# max32665 register map
Vendor: Maxim-Integrated; Series: ARMCM3; File version: 1.1
CPU: CM4 r2p1, little endian, MPU, FPU, 3 interrupt priority bits
Registers are 32-bit, read-write, reset 0x0 unless marked. A register's access mark holds for its fields unless they carry their own. Offsets are from the block's base; [hi:lo] are bit positions; 'fields as' and 'values as' point back to an identical list.

## TRIMSIR — Trim System Initilazation Registers
Base 0x40005400
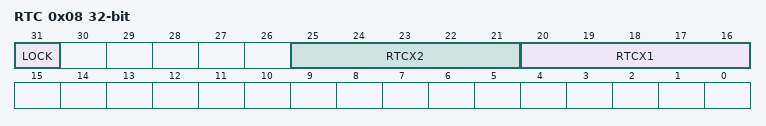
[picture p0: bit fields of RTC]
0x08 RTC — System Init. Configuration Register 2.
  [31] LOCK
  [25:21] RTCX2 — RTC X2 Trim.
  [20:16] RTCX1 — RTC X1 Trim.
0x34 SIR13 — System Init. Configuration Register 13.
  [1:0] SIMOCLKDIV — SIMO Clock Divide while in LP mode.
0x44 SIR17 — System Init. Configuration Register 17.
  [7:6] BUCKCLKSELLP — BUCK Clock Select Low Power Mode.

## WDT0 — Watchdog Timer 0
Base 0x40003000
Same registers: WDT1 0x40003400, WDT2 0x40003800
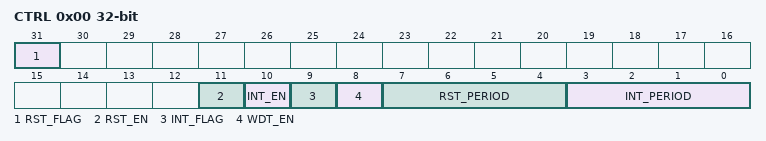
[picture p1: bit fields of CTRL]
0x00 CTRL (reset mask 0x7FFFF000) — Watchdog Timer Control Register.
  [31] RST_FLAG — Watchdog Timer Reset Flag.
    0=noEvent (The event has not occurred.); 1=occurred (The event has occurred.)
  [11] RST_EN — Watchdog Timer Reset Enable.
    0=dis (Disable.); 1=en (Enable.)
  [10] INT_EN — Watchdog Timer Interrupt Enable.
    0=dis (Disable.); 1=en (Enable.)
  [9] INT_FLAG write-1-clears — Watchdog Timer Interrupt Flag.
    0=inactive (No interrupt is pending.); 1=pending (An interrupt is pending.)
  [8] WDT_EN — Watchdog Timer Enable.
    0=dis (Disable.); 1=en (Enable.)
  [7:4] RST_PERIOD — Watchdog Reset Period. The watchdog timer will assert a reset, if enabled, if the CPU does not write the watchdog reset sequence to the WDT_RST register before the watchdog timer has counted this time period since the last timer reset.
    0=wdt2pow31 (2**31 clock cycles.); 1=wdt2pow30 (2**30 clock cycles.); 2=wdt2pow29 (2**29 clock cycles.); 3=wdt2pow28 (2**28 clock cycles.); 4=wdt2pow27 (2^27 clock cycles.); 5=wdt2pow26 (2**26 clock cycles.); 6=wdt2pow25 (2**25 clock cycles.); 7=wdt2pow24 (2**24 clock cycles.); 8=wdt2pow23 (2**23 clock cycles.); 9=wdt2pow22 (2**22 clock cycles.); 10=wdt2pow21 (2**21 clock cycles.); 11=wdt2pow20 (2**20 clock cycles.); 12=wdt2pow19 (2**19 clock cycles.); 13=wdt2pow18 (2**18 clock cycles.); 14=wdt2pow17 (2**17 clock cycles.); 15=wdt2pow16 (2**16 clock cycles.)
  [3:0] INT_PERIOD — Watchdog Interrupt Period. The watchdog timer will assert an interrupt, if enabled, if the CPU does not write the watchdog reset sequence to the WDT_RST register before the watchdog timer has counted this time period since the last timer reset.
    values as RST_PERIOD
0x04 RST wo — Watchdog Timer Reset Register.
  [7:0] WDT_RST — Writing the watchdog counter 'reset sequence' to this register resets the watchdog counter. If the watchdog count exceeds INT_PERIOD then a watchdog interrupt will occur, if enabled. If the watchdog count exceeds RST_PERIOD then a watchdog reset will occur, if enabled.
    165=seq0 (The first value to be written to reset the WDT.); 90=seq1 (The second value to be written to reset the WDT.)

## WUT — Wake Up Timer
Base 0x40006400
0x00 CNT — Wakeup Timer Count Register
  [31:0] COUNT — Timer Count Value.
0x04 CMP — Wakeup Timer Compare Register
  [31:0] COMPARE — Timer Compare Value.
0x0C INTFL — Wakeup Timer Interrupt Register
  [0] IRQ_CLR — Timer Interrupt.
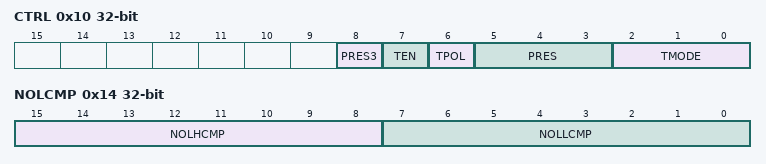
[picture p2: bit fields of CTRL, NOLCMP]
0x10 CTRL — Wakeup Timer Control Register
  [8] PRES3 — Timer Prescaler Select.
    0=pres3_1; 0=pres3_2; 0=pres3_4; 0=pres3_8; 0=pres3_16; 0=pres3_32; 0=pres3_64; 0=pres3_128; 1=pres3_256; 1=pres3_512; 1=pres3_1024; 1=pres3_2048; 1=pres3_4096
  [7] TEN — Timer Enable.
    0=timer_dis; 1=timer_en
  [6] TPOL — Timer Polarity.
  [5:3] PRES — Timer Prescaler Select.
    0=DIV1; 1=DIV2; 2=DIV4; 3=DIV8; 4=DIV16; 5=DIV32; 6=DIV64; 7=DIV128; 0=DIV256; 2=DIV512; 3=DIV1024; 4=DIV2048; 5=DIV4096
  [2:0] TMODE — Timer Mode Select.
    0=One Shot Mode; 1=Continuous Mode; 2=Counter Mode; 3=pwm (PWM Mode.); 4=Capture Mode; 5=Compare Mode; 6=Gated Mode; 7=Capture/Compare Mode
0x14 NOLCMP — Non Overlaping Compare Register
  [15:8] NOLHCMP — Non Overlaping High Compare.
  [7:0] NOLLCMP — Non Overlaping Low Compare.
0x18 PRESET
  [31:0] PRESET — Preset Value.
0x1C RELOAD
  [31:0] RELOAD — Reload Value.
0x20 SNAPSHOT
  [31:0] SNAPSHOT — Snapshot Value.
